AUTOSAR XML (schema 4-0-3)
standard types defined: UInt16
package /AUTOSAR_Platform/DataConstrs
  range DC_UInt16: raw 0..65535
package /PATAC/MSM/ComponentTypes
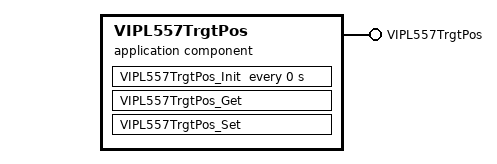
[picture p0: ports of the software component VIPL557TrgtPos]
  application sw component type VIPL557TrgtPos
    provide port VIPL557TrgtPos: provided-com-specs=[{operation=Get, queue-length=1}, {operation=Set, queue-length=1}], provided-interface=VIPL557TrgtPos
    behavior VIPL557TrgtPos_InternalBehavior
      operation invoked event OIT_VIPL557TrgtPos_Get_VIPL557TrgtPos_Get: start-on-event=VIPL557TrgtPos_Get, operation=VIPL557TrgtPos.Get
      timing event VIPL557TrgtPos_InitEvent: start-on-event=VIPL557TrgtPos_Init, period=0
      operation invoked event OIT_VIPL557TrgtPos_Set_VIPL557TrgtPos_Set: start-on-event=VIPL557TrgtPos_Set, operation=VIPL557TrgtPos.Set
      runnable VIPL557TrgtPos_Get
      runnable VIPL557TrgtPos_Init
      runnable VIPL557TrgtPos_Set
  swc implementation VIPL557TrgtPos_Implementation: behavior=VIPL557TrgtPos_InternalBehavior
    code-descriptors:
      code Default: artifact-descriptors=autosar-engineering-object={short-label=Default, category=SWSRC}
package /PATAC/MSM/ModeAdjust/PortInterface
  client server interface VIPL557TrgtPos
    operation Get
      5 x arg, all with type=UInt16, direction=OUT, server-argument-impl-policy=USE-ARGUMENT-TYPE:
        SecRwLtStBkReclnTrgtPos
        SecRwLtStZeroTrgtPos
        SecRwLtStLgrstUpwdDnwdTrgtPos
        SecRwLtStLgrstInwdOtwdTrgtPos
        SecRwLtStFwdBkwdTrgtPos
    operation Set
      5 x arg, all with type=UInt16, direction=IN, server-argument-impl-policy=USE-ARGUMENT-TYPE:
        SecRwLtStBkReclnTrgtPos
        SecRwLtStZeroTrgtPos
        SecRwLtStLgrstUpwdDnwdTrgtPos
        SecRwLtStLgrstInwdOtwdTrgtPos
        SecRwLtStFwdBkwdTrgtPos
